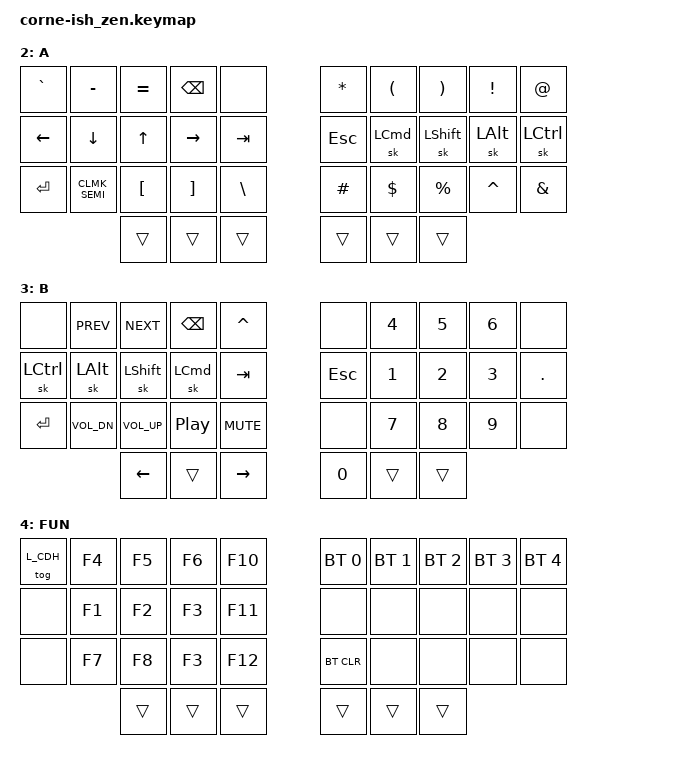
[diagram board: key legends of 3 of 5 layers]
// Set tab size to 8.

#include <behaviors.dtsi>
#include <dt-bindings/zmk/keys.h>
#include <dt-bindings/zmk/bt.h>

#define CLMK_A A
#define CLMK_E K
#define CLMK_O SEMICOLON
#define CLMK_U I
#define CLMK_SEMI P
#define CLMK_COLON LS(P)

#define L_BASE 0
#define L_CDH 1
#define L_A 2
#define L_B 3
#define L_FUN 4

#define BASE_LAYERS L_BASE L_CDH

#define COMBO(NAME, LAYERS, POSITIONS, BINDINGS) \
	combo_##NAME { \
		timeout-ms = <50>; \
		key-positions = <POSITIONS>; \
		bindings = <BINDINGS>; \
		layers = <LAYERS>; \
	}

// ,-----------------------------.   ,-----------------------------.
// |     |     |     |     |     |   |     |     |     |     |     |
// |     |     |     |     |     |   |     |     |     |     |     |
// |     |     |     |     |     |   |     |     |     |     |     |
// `-----------|     |     |     |   |     |     |     |-----------'
//             `-----------------'   `-----------------'

// Key Positions
// ,-----------------------------.   ,-----------------------------.
// |  0  |  1  |  2  |  3  |  4  |   |  5  |  6  |  7  |  8  |  9  |
// | 10  | 11  | 12  | 13  | 14  |   | 15  | 16  | 17  | 18  | 19  |
// | 20  | 21  | 22  | 23  | 24  |   | 25  | 26  | 27  | 28  | 29  |
// `-----------| 30  | 31  | 32  |   | 33  | 34  | 35  |-----------'
//             `-----------------'   `-----------------'

/ {
	behaviors {
		// Quick-release shift - always release it after
		// the next typed key.
		skq: sticky_key_quick_release {
			compatible = "zmk,behavior-sticky-key";
			label = "STICKY_KEY_QUICK_RELEASE";
			#binding-cells = <1>;
			bindings = <&kp>;
			release-after-ms = <1000>;
			quick-release;
		};

		// Make it so you have to tap cmd-q for a while.
		q_guard: q_guard_morph {
			compatible = "zmk,behavior-mod-morph";
			label = "Q_GUARD_MORPH";
			#binding-cells = <0>;
			bindings = <&kp Q>, <&q_td>;
			mods = <MOD_LGUI>;
		};
		q_td: q_tap_dance {
			compatible = "zmk,behavior-tap-dance";
			label = "Q_TAP_DANCE";
			#binding-cells = <0>;
			tapping-term-ms = <200>;
			bindings = <&none>, <&kp Q>;
		};
	};

	macros {
        };

	keymap {
		compatible = "zmk,keymap";

		// Base layer.
		// The shift acts as a tab to make typing SCREAMING_SNAKE case
		// easier.
		default_layer {
			label = "BASE";
// ,-----------------------------.   ,-----------------------------.
// |  Q  |  W  |  E  |  R  |  R  |   |  Y  |  U  |  I  |  O  |  '  |
// |  A  |  S  |  D  |  F  |  D  |   |  H  |  J  |  K  |  L  |  ;  |
// |  Z  |  X  |  C  |  V  |  B  |   |  N  |  M  |  ,  |  .  |  /  |
// `-----------| fun |  a  | SPC |   |  b  | SFT | DIS |-----------'
//             `-----------------'   `-----------------'
			bindings = <
&q_guard	&kp W		&kp E		&kp R		&kp T		&kp Y		&kp U		&kp I		&kp O		&kp APOS
&kp A		&kp S		&kp D		&kp F		&kp G		&kp H		&kp J		&kp K		&kp L		&kp CLMK_O
&kp Z		&kp X		&kp C		&kp V		&kp B		&kp N		&kp M		&kp COMMA	&kp DOT		&kp SLASH
#define THUMB_ROW \
				&sl L_FUN	&sl L_B		&kp SPACE	&sl L_A		&skq LSHIFT  	&none
THUMB_ROW
			>;
		};

		// Same as above but hard-coded Colemak.
		// Note right now there is no handy way to type : and ;
		colemak_layer {
			label = "CDH";
// ,-----------------------------.   ,-----------------------------.
// |  Q  |  W  |  F  |  P  |  G  |   |  J  |  L  |  U  |  Y  |  '  |
// |  A  |  R  |  S  |  T  |  D  |   |  H  |  N  |  E  |  I  |  O  |
// |  Z  |  X  |  C  |  V  |  B  |   |  K  |  M  |  ,  |  .  |  /  |
// `-----------| ... | ... | ... |   | ... | ... | ... |-----------'
//             `-----------------'   `-----------------'
			bindings = <
&q_guard	&kp W		&kp F		&kp P		&kp G		&kp J		&kp L		&kp U		&kp Y		&kp APOS
&kp A		&kp R		&kp S		&kp T		&kp D		&kp H		&kp N		&kp E		&kp I		&kp O
&kp Z		&kp X		&kp C		&kp V		&kp B		&kp K		&kp M		&kp COMMA	&kp DOT		&kp SLASH
THUMB_ROW
			>;
		};

		// Layer A.
		// The base layer already contains many special characters
		// , . / '               The characters on the base layer
		// < > ? "               Their shifts
		//
		// The remianing "base" special characters should go on the left
		// to make any modifier-heavy shortcut is easy to type.
		// \ [ ] = - ` ;         The missing base qwerty characters
		// | { } + _ ~ :         Their shifts
		//
		// Really the only problem is the number-based special
		// characters, which go on the right.
		// ! @ # $ % ^ & * ( )   Number-based special characters
		//
		// If you read left to right from ! and wrap around you will
		// note the order exactly matches the number row.
		// This rotation is here to to make ( ) easy to type and to
		// keep * and # together for Vim.
		a_layer {
			label = "A";
// ,-----------------------------.   ,-----------------------------.
// |  `  |  -  |  =  | BSP |     |   |  *  |  (  |  )  |  !  |  @  |
// | LFT | DWN | UP  | RGH | TAB |   | ESC |  ⌘  |  ⇧  |  ⎇  |  ⌃  |
// | ENT |  ;  |  [  |  ]  |  \  |   |  #  |  $  |  %  |  ^  |  &  |
// `-----------|     |     | SPC |   | XXX |     |     |-----------'
//             `-----------------'   `-----------------'
			bindings = <
&kp GRAVE	&kp MINUS	&kp EQUAL	&kp BSPC	&none		&kp ASTERISK	&kp LPAR	&kp RPAR	&kp EXCLAMATION	&kp AT_SIGN
&kp LEFT	&kp DOWN	&kp UP		&kp RIGHT	&kp TAB		&kp ESC		&sk LCMD	&sk LSHIFT	&sk LALT	&sk LCTRL
&kp ENTER	&kp CLMK_SEMI	&kp LBKT	&kp RBKT	&kp BACKSLASH	&kp HASH	&kp DOLLAR	&kp PERCENT	&kp CARET	&kp AMPERSAND
				&trans		&trans		&trans		&trans		&trans		&trans
			>;
		};

		// Layer B.
		// The media keys, enter, and lock are on thumb-side for
		// one-handed use. Left and right arrows are duplicated
		// around the thumb-key. The idea is you press the
		// thumb-key with the the middle finger then use index and
		// ring fingers to control video playback.
		b_layer {
			label = "B";
// ,-----------------------------.   ,-----------------------------.
// |     | PRV | NXT | BSP |     |   |     |  4  |  5  |  6  |     |
// |  ⌃  |  ⎇  |  ⇧  |  ⌘  | TAB |   | ESC |  1  |  2  |  3  |  .  |
// | ENT | VDW | VUP | PLY | MUT |   |     |  7  |  8  |  9  |     |
// `-----------| LFT | XXX | RGH |   |  0  |     |     |-----------'
//             `-----------------'   `-----------------'
			bindings = <
&none		&kp C_PREV	&kp C_NEXT	&kp BSPC	&kp CARET	&none		&kp N4		&kp N5		&kp N6		&none
&sk LCTRL	&sk LALT	&sk LSHIFT	&sk LCMD	&kp TAB		&kp ESC		&kp N1		&kp N2		&kp N3		&kp DOT
&kp ENTER	&kp C_VOL_DN	&kp C_VOL_UP	&kp C_PP	&kp C_MUTE	&none		&kp N7		&kp N8		&kp N9		&none
				&kp LEFT	&trans		&kp RIGHT	&kp N0		&trans		&trans
			>;
		};


		//TODO: The mouse keys will go on the right hand side once zmk #778 is merged.
		fun_layer {
			label = "FUN";
// ,-----------------------------.   ,-----------------------------.
// | CDH | F4  | F5  | F6  | F10 |   | BT0 | BT1 | BT2 | BT3 | BT4 |
// |     | F1  | F2  | F3  | F11 |   |     |     |     |     |     |
// |     | F7  | F8  | F9  | F12 |   | BTC |     |     |     |     |
// `-----------| XXX |     |     |   |     |     |     |-----------'
//             `-----------------'   `-----------------'
			bindings = <
&tog L_CDH	&kp F4		&kp F5		&kp F6		&kp F10		&bt BT_SEL 0	&bt BT_SEL 1	&bt BT_SEL 2	&bt BT_SEL 3	&bt BT_SEL 4
&none		&kp F1		&kp F2		&kp F3		&kp F11		&none		&none		&none		&none		&none
&none		&kp F7		&kp F8		&kp F3		&kp F12		&bt BT_CLR	&none		&none		&none		&none
				&trans		&trans		&trans		&trans		&trans		&trans
			>;
		};
	};

	chosen {
		zmk,matrix_transform = &five_column_transform;
	};
};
